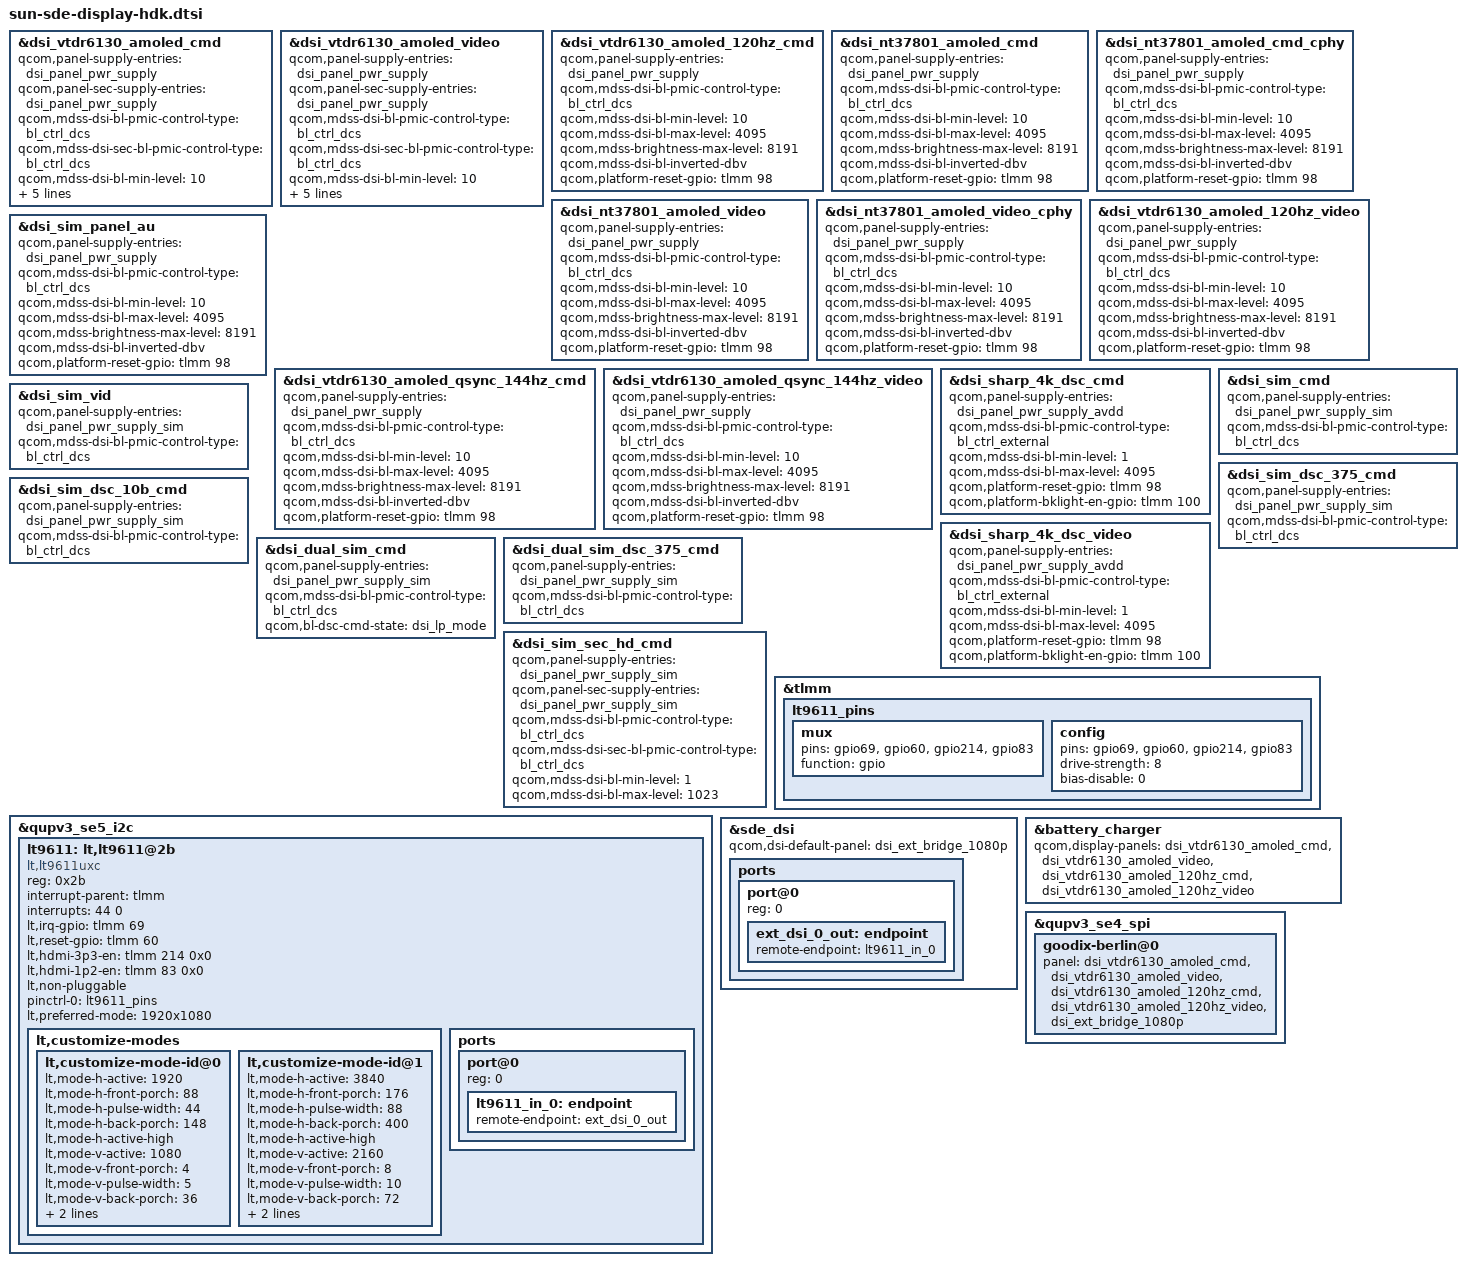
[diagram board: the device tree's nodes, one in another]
// SPDX-License-Identifier: BSD-3-Clause
/*
 * Copyright (c) 2024, Qualcomm Innovation Center, Inc. All rights reserved.
 */

#include "sun-sde-display.dtsi"

&dsi_vtdr6130_amoled_cmd {
	qcom,panel-supply-entries = <&dsi_panel_pwr_supply>;
	qcom,panel-sec-supply-entries = <&dsi_panel_pwr_supply>;
	qcom,mdss-dsi-bl-pmic-control-type = "bl_ctrl_dcs";
	qcom,mdss-dsi-sec-bl-pmic-control-type = "bl_ctrl_dcs";
	qcom,mdss-dsi-bl-min-level = <10>;
	qcom,mdss-dsi-bl-max-level = <4095>;
	qcom,mdss-brightness-max-level = <8191>;
	qcom,mdss-dsi-bl-inverted-dbv;
	qcom,platform-reset-gpio = <&tlmm 98 0>;
	qcom,platform-sec-reset-gpio = <&tlmm 97 0>;
};

&dsi_vtdr6130_amoled_video {
	qcom,panel-supply-entries = <&dsi_panel_pwr_supply>;
	qcom,panel-sec-supply-entries = <&dsi_panel_pwr_supply>;
	qcom,mdss-dsi-bl-pmic-control-type = "bl_ctrl_dcs";
	qcom,mdss-dsi-sec-bl-pmic-control-type = "bl_ctrl_dcs";
	qcom,mdss-dsi-bl-min-level = <10>;
	qcom,mdss-dsi-bl-max-level = <4095>;
	qcom,mdss-brightness-max-level = <8191>;
	qcom,mdss-dsi-bl-inverted-dbv;
	qcom,platform-reset-gpio = <&tlmm 98 0>;
	qcom,platform-sec-reset-gpio = <&tlmm 97 0>;
};

&dsi_vtdr6130_amoled_120hz_cmd {
	qcom,panel-supply-entries = <&dsi_panel_pwr_supply>;
	qcom,mdss-dsi-bl-pmic-control-type = "bl_ctrl_dcs";
	qcom,mdss-dsi-bl-min-level = <10>;
	qcom,mdss-dsi-bl-max-level = <4095>;
	qcom,mdss-brightness-max-level = <8191>;
	qcom,mdss-dsi-bl-inverted-dbv;
	qcom,platform-reset-gpio = <&tlmm 98 0>;
};

&dsi_nt37801_amoled_cmd {
	qcom,panel-supply-entries = <&dsi_panel_pwr_supply>;
	qcom,mdss-dsi-bl-pmic-control-type = "bl_ctrl_dcs";
	qcom,mdss-dsi-bl-min-level = <10>;
	qcom,mdss-dsi-bl-max-level = <4095>;
	qcom,mdss-brightness-max-level = <8191>;
	qcom,mdss-dsi-bl-inverted-dbv;
	qcom,platform-reset-gpio = <&tlmm 98 0>;
};

&dsi_nt37801_amoled_cmd_cphy {
	qcom,panel-supply-entries = <&dsi_panel_pwr_supply>;
	qcom,mdss-dsi-bl-pmic-control-type = "bl_ctrl_dcs";
	qcom,mdss-dsi-bl-min-level = <10>;
	qcom,mdss-dsi-bl-max-level = <4095>;
	qcom,mdss-brightness-max-level = <8191>;
	qcom,mdss-dsi-bl-inverted-dbv;
	qcom,platform-reset-gpio = <&tlmm 98 0>;
};

&dsi_nt37801_amoled_video {
	qcom,panel-supply-entries = <&dsi_panel_pwr_supply>;
	qcom,mdss-dsi-bl-pmic-control-type = "bl_ctrl_dcs";
	qcom,mdss-dsi-bl-min-level = <10>;
	qcom,mdss-dsi-bl-max-level = <4095>;
	qcom,mdss-brightness-max-level = <8191>;
	qcom,mdss-dsi-bl-inverted-dbv;
	qcom,platform-reset-gpio = <&tlmm 98 0>;
};

&dsi_nt37801_amoled_video_cphy {
	qcom,panel-supply-entries = <&dsi_panel_pwr_supply>;
	qcom,mdss-dsi-bl-pmic-control-type = "bl_ctrl_dcs";
	qcom,mdss-dsi-bl-min-level = <10>;
	qcom,mdss-dsi-bl-max-level = <4095>;
	qcom,mdss-brightness-max-level = <8191>;
	qcom,mdss-dsi-bl-inverted-dbv;
	qcom,platform-reset-gpio = <&tlmm 98 0>;
};

&dsi_vtdr6130_amoled_120hz_video {
	qcom,panel-supply-entries = <&dsi_panel_pwr_supply>;
	qcom,mdss-dsi-bl-pmic-control-type = "bl_ctrl_dcs";
	qcom,mdss-dsi-bl-min-level = <10>;
	qcom,mdss-dsi-bl-max-level = <4095>;
	qcom,mdss-brightness-max-level = <8191>;
	qcom,mdss-dsi-bl-inverted-dbv;
	qcom,platform-reset-gpio = <&tlmm 98 0>;
};

&dsi_sim_panel_au {
	qcom,panel-supply-entries = <&dsi_panel_pwr_supply>;
	qcom,mdss-dsi-bl-pmic-control-type = "bl_ctrl_dcs";
	qcom,mdss-dsi-bl-min-level = <10>;
	qcom,mdss-dsi-bl-max-level = <4095>;
	qcom,mdss-brightness-max-level = <8191>;
	qcom,mdss-dsi-bl-inverted-dbv;
	qcom,platform-reset-gpio = <&tlmm 98 0>;
};

&dsi_vtdr6130_amoled_qsync_144hz_cmd {
	qcom,panel-supply-entries = <&dsi_panel_pwr_supply>;
	qcom,mdss-dsi-bl-pmic-control-type = "bl_ctrl_dcs";
	qcom,mdss-dsi-bl-min-level = <10>;
	qcom,mdss-dsi-bl-max-level = <4095>;
	qcom,mdss-brightness-max-level = <8191>;
	qcom,mdss-dsi-bl-inverted-dbv;
	qcom,platform-reset-gpio = <&tlmm 98 0>;
};

&dsi_vtdr6130_amoled_qsync_144hz_video {
	qcom,panel-supply-entries = <&dsi_panel_pwr_supply>;
	qcom,mdss-dsi-bl-pmic-control-type = "bl_ctrl_dcs";
	qcom,mdss-dsi-bl-min-level = <10>;
	qcom,mdss-dsi-bl-max-level = <4095>;
	qcom,mdss-brightness-max-level = <8191>;
	qcom,mdss-dsi-bl-inverted-dbv;
	qcom,platform-reset-gpio = <&tlmm 98 0>;
};

&dsi_sharp_4k_dsc_cmd {
	qcom,panel-supply-entries = <&dsi_panel_pwr_supply_avdd>;
	qcom,mdss-dsi-bl-pmic-control-type = "bl_ctrl_external";
	qcom,mdss-dsi-bl-min-level = <1>;
	qcom,mdss-dsi-bl-max-level = <4095>;
	qcom,platform-reset-gpio = <&tlmm 98 0>;
	qcom,platform-bklight-en-gpio = <&tlmm 100 0>;
};

&dsi_sharp_4k_dsc_video {
	qcom,panel-supply-entries = <&dsi_panel_pwr_supply_avdd>;
	qcom,mdss-dsi-bl-pmic-control-type = "bl_ctrl_external";
	qcom,mdss-dsi-bl-min-level = <1>;
	qcom,mdss-dsi-bl-max-level = <4095>;
	qcom,platform-reset-gpio = <&tlmm 98 0>;
	qcom,platform-bklight-en-gpio = <&tlmm 100 0>;
};

&dsi_sim_cmd {
	qcom,panel-supply-entries = <&dsi_panel_pwr_supply_sim>;
	qcom,mdss-dsi-bl-pmic-control-type = "bl_ctrl_dcs";
};

&dsi_sim_vid {
	qcom,panel-supply-entries = <&dsi_panel_pwr_supply_sim>;
	qcom,mdss-dsi-bl-pmic-control-type = "bl_ctrl_dcs";
};

&dsi_sim_dsc_375_cmd {
	qcom,panel-supply-entries = <&dsi_panel_pwr_supply_sim>;
	qcom,mdss-dsi-bl-pmic-control-type = "bl_ctrl_dcs";
};

&dsi_sim_dsc_10b_cmd {
	qcom,panel-supply-entries = <&dsi_panel_pwr_supply_sim>;
	qcom,mdss-dsi-bl-pmic-control-type = "bl_ctrl_dcs";
};

&dsi_dual_sim_cmd {
	qcom,panel-supply-entries = <&dsi_panel_pwr_supply_sim>;
	qcom,mdss-dsi-bl-pmic-control-type = "bl_ctrl_dcs";
	qcom,bl-dsc-cmd-state = "dsi_lp_mode";
};

&dsi_dual_sim_dsc_375_cmd {
	qcom,panel-supply-entries = <&dsi_panel_pwr_supply_sim>;
	qcom,mdss-dsi-bl-pmic-control-type = "bl_ctrl_dcs";
};

&dsi_sim_sec_hd_cmd {
	qcom,panel-supply-entries = <&dsi_panel_pwr_supply_sim>;
	qcom,panel-sec-supply-entries = <&dsi_panel_pwr_supply_sim>;
	qcom,mdss-dsi-bl-pmic-control-type = "bl_ctrl_dcs";
	qcom,mdss-dsi-sec-bl-pmic-control-type = "bl_ctrl_dcs";
	qcom,mdss-dsi-bl-min-level = <1>;
	qcom,mdss-dsi-bl-max-level = <1023>;
};

&tlmm {
	lt9611_pins: lt9611_pins {
		mux {
			pins = "gpio69", "gpio60", "gpio214", "gpio83";
			function = "gpio";
		};

		config {
			pins = "gpio69", "gpio60", "gpio214", "gpio83";
			drive-strength = <8>;
			bias-disable = <0>;
		};
	};
};

&qupv3_se5_i2c {
	status = "ok";

	lt9611: lt,lt9611@2b {
		compatible = "lt,lt9611uxc";
		reg = <0x2b>;
		interrupt-parent = <&tlmm>;
		interrupts = <44 0>;
		interrupt-names = "lt_irq";
		lt,irq-gpio = <&tlmm 69 0x0>;
		lt,reset-gpio = <&tlmm 60 0x0>;
		lt,hdmi-3p3-en = <&tlmm 214 0x0>;
		lt,hdmi-1p2-en = <&tlmm 83 0x0>;
		lt,non-pluggable;

		pinctrl-names = "default";
		pinctrl-0 = <&lt9611_pins>;

		lt,preferred-mode = "1920x1080";

		lt,customize-modes {
			lt,customize-mode-id@0 {
				lt,mode-h-active = <1920>;
				lt,mode-h-front-porch = <88>;
				lt,mode-h-pulse-width = <44>;
				lt,mode-h-back-porch = <148>;
				lt,mode-h-active-high;
				lt,mode-v-active = <1080>;
				lt,mode-v-front-porch = <4>;
				lt,mode-v-pulse-width = <5>;
				lt,mode-v-back-porch = <36>;
				lt,mode-v-active-high;
				lt,mode-clock-in-khz = <148500>;
			};

			lt,customize-mode-id@1 {
				lt,mode-h-active = <3840>;
				lt,mode-h-front-porch = <176>;
				lt,mode-h-pulse-width = <88>;
				lt,mode-h-back-porch = <400>;
				lt,mode-h-active-high;
				lt,mode-v-active = <2160>;
				lt,mode-v-front-porch = <8>;
				lt,mode-v-pulse-width = <10>;
				lt,mode-v-back-porch = <72>;
				lt,mode-v-active-high;
				lt,mode-clock-in-khz = <608040>;
			};
		};

		ports {
			#address-cells = <1>;
			#size-cells = <0>;

			port@0 {
				reg = <0>;
				lt9611_in_0: endpoint {
					remote-endpoint = <&ext_dsi_0_out>;
				};
			};
		};
	};
};

&sde_dsi {
	qcom,dsi-default-panel = <&dsi_ext_bridge_1080p>;
	ports {
		#address-cells = <1>;
		#size-cells = <0>;

		port@0 {
			reg = <0>;
			ext_dsi_0_out: endpoint {
				remote-endpoint = <&lt9611_in_0>;
			};
		};
	};
};

&battery_charger {
	qcom,display-panels = <&dsi_vtdr6130_amoled_cmd
			      &dsi_vtdr6130_amoled_video
			      &dsi_vtdr6130_amoled_120hz_cmd
			      &dsi_vtdr6130_amoled_120hz_video>;
};

&qupv3_se4_spi {
	goodix-berlin@0 {
		panel = <&dsi_vtdr6130_amoled_cmd
			&dsi_vtdr6130_amoled_video
			&dsi_vtdr6130_amoled_120hz_cmd
			&dsi_vtdr6130_amoled_120hz_video
			&dsi_ext_bridge_1080p>;
	};
};
